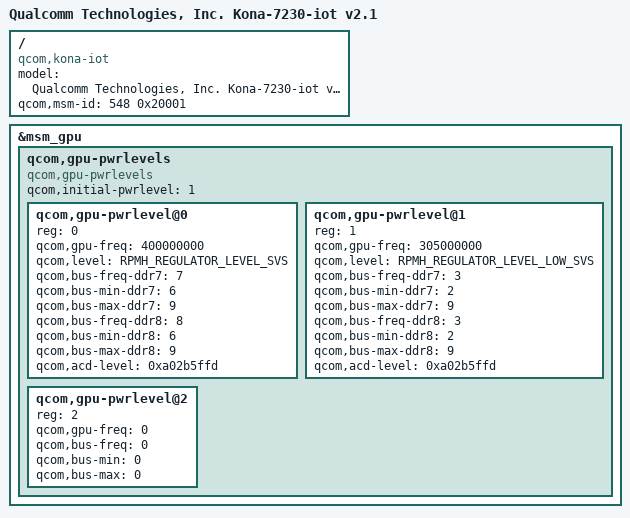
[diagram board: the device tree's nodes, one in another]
#include "kona-iot-v2.1.dtsi"
#include "kona-7230-iot-cpu.dtsi"

/ {
	model = "Qualcomm Technologies, Inc. Kona-7230-iot v2.1";
	compatible = "qcom,kona-iot";
	qcom,msm-id = <548 0x20001>;
};

&msm_gpu {
	/delete-property/qcom,gpu-speed-bin;
	/delete-property/qcom,initial-pwrlevel;
	/delete-node/qcom,gpu-pwrlevels;
	/delete-node/qcom,gpu-pwrlevel-bins;

	/* GPU power levels */
	qcom,gpu-pwrlevels {
			compatible = "qcom,gpu-pwrlevels";
			#address-cells = <1>;
			#size-cells = <0>;
			qcom,initial-pwrlevel = <1>;

			qcom,gpu-pwrlevel@0 {
					reg = <0>;
					qcom,gpu-freq = <400000000>;
					qcom,level = <RPMH_REGULATOR_LEVEL_SVS>;

					qcom,bus-freq-ddr7 = <7>;
					qcom,bus-min-ddr7 = <6>;
					qcom,bus-max-ddr7 = <9>;

					qcom,bus-freq-ddr8 = <8>;
					qcom,bus-min-ddr8 = <6>;
					qcom,bus-max-ddr8 = <9>;

					qcom,acd-level = <0xa02b5ffd>;
			};

			qcom,gpu-pwrlevel@1 {
					reg = <1>;
					qcom,gpu-freq = <305000000>;
					qcom,level = <RPMH_REGULATOR_LEVEL_LOW_SVS>;

					qcom,bus-freq-ddr7 = <3>;
					qcom,bus-min-ddr7 = <2>;
					qcom,bus-max-ddr7 = <9>;

					qcom,bus-freq-ddr8 = <3>;
					qcom,bus-min-ddr8 = <2>;
					qcom,bus-max-ddr8 = <9>;

					qcom,acd-level = <0xa02b5ffd>;
			};

			qcom,gpu-pwrlevel@2 {
					reg = <2>;
					qcom,gpu-freq = <0>;
					qcom,bus-freq = <0>;
					qcom,bus-min = <0>;
					qcom,bus-max = <0>;
			};
	};
};

